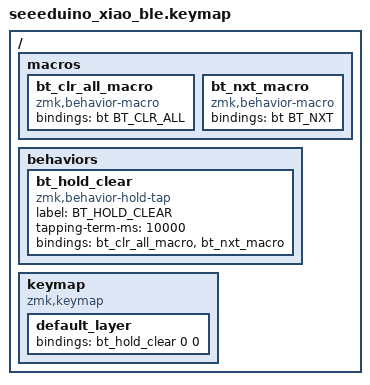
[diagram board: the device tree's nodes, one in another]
#include <behaviors.dtsi>
#include <dt-bindings/zmk/keys.h>
#include <dt-bindings/zmk/bt.h>

/ {
    macros {
        // Each macro hardcodes its BT command, so it takes 0 parameters.
        // (BT_CLR_ALL and BT_NXT each already expand to 2 cells themselves —
        // wrapping &bt directly in the hold-tap below would have forwarded
        // those 2 cells straight through, mismatching its declared cell count.)
        bt_clr_all_macro: bt_clr_all_macro {
            compatible = "zmk,behavior-macro";
            #binding-cells = <0>;
            bindings = <&bt BT_CLR_ALL>;
        };

        bt_nxt_macro: bt_nxt_macro {
            compatible = "zmk,behavior-macro";
            #binding-cells = <0>;
            bindings = <&bt BT_NXT>;
        };
    };

    behaviors {
        // Tap D9 = next BT profile (pairing). Hold 10s = clear ALL profiles,
        // as an escape hatch if pairing gets stuck with all 5 slots used up
        // or corrupted. No release-timeout race to worry about here since
        // there's no other key on this device to interrupt the hold decision.
        // #binding-cells must be 2 here — ZMK's hold-tap schema hardcodes
        // that regardless of what's wrapped. The 2 values are forwarded to
        // the macros below, which ignore them (they just replay a fixed
        // &bt binding), so the actual numbers passed don't matter.
        bt_hold_clear: bt_hold_clear {
            compatible = "zmk,behavior-hold-tap";
            label = "BT_HOLD_CLEAR";
            #binding-cells = <2>;
            tapping-term-ms = <10000>;
            bindings = <&bt_clr_all_macro>, <&bt_nxt_macro>;
        };
    };

    keymap {
        compatible = "zmk,keymap";

        default_layer {
            // Position 0 = D9 button: tap to pair (BT_NXT), hold 10s to
            // clear all 5 BT profiles if pairing ever gets stuck.
            // Position 1 = D10 button: drop into the UF2 bootloader, so you
            // can reflash without needing physical access to the XIAO's own
            // reset button once the trackpad is inside a closed case.
            bindings = <&bt_hold_clear 0 0>;
        };
    };
};
